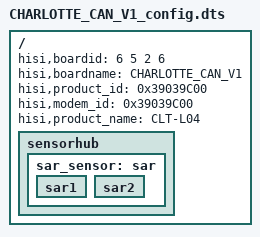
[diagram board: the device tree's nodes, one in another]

/**
 * Copyright (C) 2014 Hisilicon Ltd.
 *
 *  This program is free software; you can redistribute it and/or modify
 *  it under the terms of the GNU General Public License version 2 as
 *  publishhed by the Free Software Foundation.
 */

/dts-v1/;
/include/ "fastboot.dtsi"
/include/ "CHARLOTTE_LX9_V3_config.dtsi"
/include/ "CHARLOTTE_CAN_V1_pin.dtsi"
/include/ "CHARLOTTE_CAN_V1_sec_pin.dtsi"
/include/ "CHARLOTTE_CAN_V1_modem_pin.dtsi"

/ {
	hisi,boardid = <6 5 2 6>;
	hisi,boardname = "CHARLOTTE_CAN_V1";
	hisi,product_id = <0x39039C00>;
	hisi,modem_id = <0x39039C00>;
	hisi,product_name = "CLT-L04";
	sensorhub{
		sar_sensor:sar{
			sar1{
				status = "ok";
			};
			sar2{
				status = "ok";
			};
		};
	};
};
